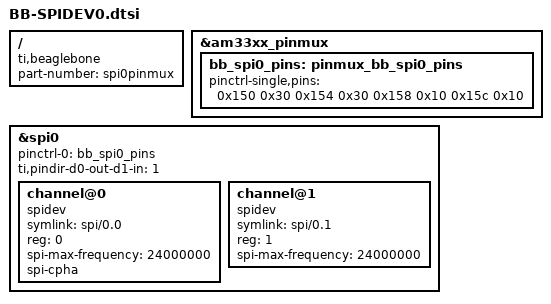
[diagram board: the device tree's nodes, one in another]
/*
 * Copyright (C) 2013 CircuitCo
 *
 * Virtual cape for SPI0 on connector pins P9.22 P9.21 P9.18 P9.17
 *
 * This program is free software; you can redistribute it and/or modify
 * it under the terms of the GNU General Public License version 2 as
 * published by the Free Software Foundation.
 */

#include <dt-bindings/board/am335x-bbw-bbb-base.h>
#include <dt-bindings/pinctrl/am33xx.h>

/ {
	compatible = "ti,beaglebone", "ti,beaglebone-black", "ti,beaglebone-green";

    /* identification */
    part-number = "spi0pinmux";
};

&am33xx_pinmux {
	bb_spi0_pins: pinmux_bb_spi0_pins {
		pinctrl-single,pins = <
            0x150 0x30  /* spi0_sclk, INPUT_PULLUP | MODE0 */
            0x154 0x30  /* spi0_d0, INPUT_PULLUP | MODE0 */
            0x158 0x10  /* spi0_d1, OUTPUT_PULLUP | MODE0 */
            0x15c 0x10  /* spi0_cs0, OUTPUT_PULLUP | MODE0 */
		>;
	};
};

&spi0 {
	#address-cells = <1>;
	#size-cells = <0>;

	status = "okay";
	pinctrl-names = "default";
	pinctrl-0 = <&bb_spi0_pins>;
	# ti,pindir-d0-out-d1-in = <1>;

	channel@0 {
		#address-cells = <1>;
		#size-cells = <0>;

		compatible = "spidev";
		symlink = "spi/0.0";

		reg = <0>;
		spi-max-frequency = <24000000>;
		spi-cpha;
	};

	channel@1 {
		#address-cells = <1>;
		#size-cells = <0>;

		compatible = "spidev";
		symlink = "spi/0.1";

		reg = <1>;
		spi-max-frequency = <24000000>;
	};
};
